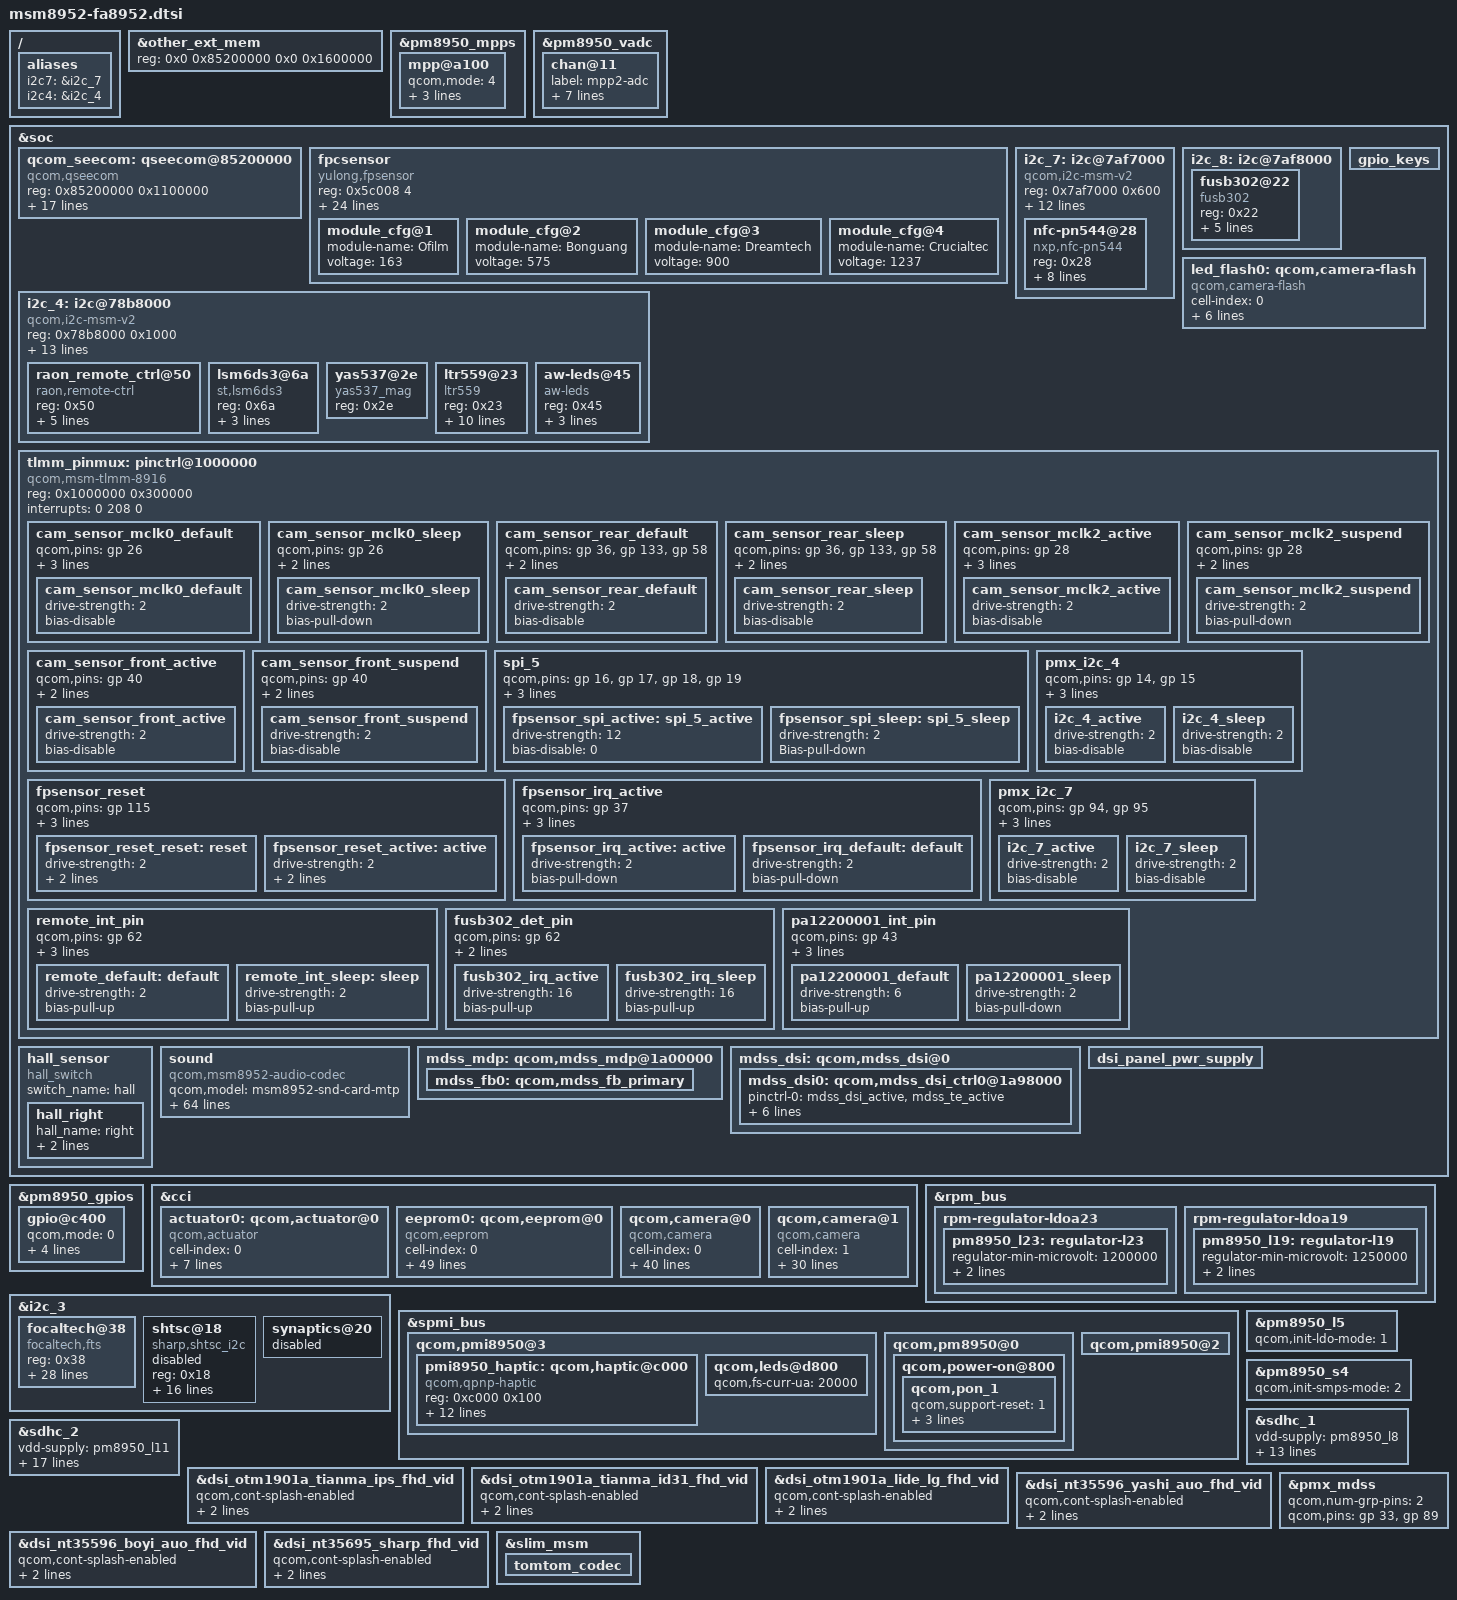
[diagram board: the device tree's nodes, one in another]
/* Copyright (c) 2014, The Linux Foundation. All rights reserved.
*
* This program is free software; you can redistribute it and/or modify
* it under the terms of the GNU General Public License version 2 and
* only version 2 as published by the Free Software Foundation.
*
* This program is distributed in the hope that it will be useful,
* but WITHOUT ANY WARRANTY; without even the implied warranty of
* MERCHANTABILITY or FITNESS FOR A PARTICULAR PURPOSE.  See the
* GNU General Public License for more details.
*/

/* project fa8952 */

/*    add by pengchaojin for NFC   */
/ {
	aliases {
		i2c7 = &i2c_7;
		i2c4 = &i2c_4;
		/delete-property/ spi0;
		/delete-property/ i2c5;
	};
	  /delete-node/ sdhc_2;
};
/*modify by huangrui*/
/*&other_ext_mem{
reg = <0x0 0x84A00000 0x0 0x1e00000>;
};*/
&other_ext_mem{
reg = <0x0 0x85200000 0x0 0x1600000>;
};

&pm8950_mpps {
         mpp@a100 {
                   status = "okay";
                   qcom,mode = <4>;
                   qcom,src-sel = <0>;
                   qcom,ain-route = <1>;
                   qcom,master-en = <1>;
         };
};

&pm8950_vadc { 
         chan@11 {
                   label ="mpp2-adc";
                   reg = <0x11>;
                   qcom,decimation = <0>;
                   qcom,pre-div-channel-scaling = <0>;
                   qcom,calibration-type = "absolute";
                   qcom,scale-function = <0>;
                   qcom,hw-settle-time = <1>;
                   qcom,fast-avg-setup = <2>;
         };
};
/* Begin add pinmux for i2c-7 */
&tlmm_pinmux {
spi_5 {
				 qcom,pins = <&gp 16>, <&gp 17>,<&gp 18>, <&gp 19>;
				 qcom,num-grp-pins = <4>;
				 qcom,pin-func = <1>;
				 label = "spi_5";
				 fpsensor_spi_active: spi_5_active {
						 drive-strength = <12>;
						 bias-disable = <0>; /* No PULL */
				 };
				 fpsensor_spi_sleep: spi_5_sleep {
						 drive-strength = <2>;
						Bias-pull-down;/*pull down*/
				 };
		};





fpsensor_reset {
			qcom,pins = <&gp 115>;
			qcom,num-grp-pins = <1>;
			qcom,pin-func = <0>;
			label = "fpsensor_reset";
			fpsensor_reset_reset: reset {
				drive-strength = <2>;
				bias-disable;
				output-low;
			};
			fpsensor_reset_active: active {
				drive-strength = <2>;
				bias-disable;
				output-high;
			};
		};

		fpsensor_irq_active {
			qcom,pins = <&gp 37>;
			qcom,num-grp-pins = <1>;
			qcom,pin-func = <0>;
			label = "fpsensor_irq_active";
			fpsensor_irq_active: active {
				drive-strength = <2>;
				bias-pull-down;
			};
			fpsensor_irq_default: default {
				drive-strength = <2>;
				bias-pull-down;
			};
		};
	
	 pmx_i2c_4 {
                 qcom,pins = <&gp 14>, <&gp 15>; /* SDA, SCL */
                 qcom,num-grp-pins = <2>;
                 qcom,pin-func = <3>;
                 label = "pmx_i2c_4";

                 i2c_4_active: i2c_4_active {
                         drive-strength = <2>;
                         bias-disable;
                    };

                  i2c_4_sleep: i2c_4_sleep {
                         drive-strength = <2>;
                         bias-disable;
                    };
          };
	pmx_i2c_7 {
		/* CLK, DATA */
		qcom,pins = <&gp 94>, <&gp 95>;
		qcom,num-grp-pins = <2>;
		qcom,pin-func = <4>;
		label = "pmx_i2c_7";
		/* active state */
		i2c_7_active: i2c_7_active{
			drive-strength = <2>; /* 2 MA */
			bias-disable; /* No PULL */
		};
		/* suspended state */
		i2c_7_sleep: i2c_7_sleep {
			drive-strength = <2>; /* 2 MA */
			bias-disable; /* No PULL */
		};
	};
	  remote_int_pin {
                qcom,pins = <&gp 62>;
                qcom,num-grp-pins = <1>;
                qcom,pin-func = <0>;
                label = "remote_wakeup_gpio";
                remote_default: default {
                        drive-strength = <2>;   /* 2 MA */
                        bias-pull-up;           /* PULL UP*/
                };
                remote_int_sleep: sleep {
                        drive-strength = <2>;   /* 2 MA */
                        bias-pull-up;           /* PULL UP */
                };
        };
        
	

	fusb302_det_pin {
		qcom,pins = <&gp 62>;
		qcom,num-grp-pins = <1>;
		label = "det-gpio";
		fusb302_irq_active: fusb302_irq_active {
			drive-strength = <16>;
			bias-pull-up;
		};
		fusb302_irq_sleep: fusb302_irq_sleep {
			drive-strength = <16>;
			bias-pull-up;
		};
	};
};
/* End add pinmux for i2c-7 */

/* Begin add i2c-7 bus */
&soc {

/*modyfy by huangrui*/
  /delete-node/ spi@78B5000;
  /delete-node/ i2c@7af5000;
    
  /delete-node/  qseecom@85e00000;
  /*qcom_seecom: qseecom@84A00000*/
   qcom_seecom: qseecom@85200000 {
		compatible = "qcom,qseecom";
		/*reg = <0x84A00000 0x1900000>;*/
		reg = <0x85200000 0x1100000>;
		reg-names = "secapp-region";
		qcom,hlos-num-ce-hw-instances = <1>;
		qcom,hlos-ce-hw-instance = <0>;
		qcom,qsee-ce-hw-instance = <0>;
		qcom,disk-encrypt-pipe-pair = <2>;
		qcom,support-fde;
		qcom,msm-bus,name = "qseecom-noc";
		qcom,msm-bus,num-cases = <4>;
		qcom,msm-bus,num-paths = <1>;
		qcom,support-bus-scaling;
		qcom,msm-bus,vectors-KBps =
			<55 512 0 0>,
			<55 512 0 0>,
			<55 512 120000 1200000>,
			<55 512 393600 3936000>;
		clocks = <&clock_gcc clk_crypto_clk_src>,
			 <&clock_gcc clk_gcc_crypto_clk>,
			 <&clock_gcc clk_gcc_crypto_ahb_clk>,
			 <&clock_gcc clk_gcc_crypto_axi_clk>;
		clock-names = "core_clk_src", "core_clk",
				"iface_clk", "bus_clk";
		qcom,ce-opp-freq = <100000000>;
	};


fpcsensor {
			status = "ok";
			compatible = "yulong,fpsensor";
			reg = <0x5c008 4>;//8939:0x5c008, 899x:0xFC4B81F0
			reg-names = "msmcpusn";
			spi-max-frequency = <10000000>;
			sensor-name = "fpc1021";//fpc1021,fpc1140,fpc1022;goodix318m,goodix518m	
			vdd_io-supply   = <&pm8950_l6>;
			//vdd_3p3-supply  = <&pm8916_l6>;
			fpsensor-vreg-name = "vdd_io";// "vdd_3p3";
			fpsensor-vreg-min-voltage = <1800000>;//3300000
			fpsensor-vreg-max-voltage = <1800000>;//3300000
			fpsensor-vreg-op-mode = <50000>;//50000
			gpio_rst    = <&msm_gpio 115 0>;
			gpio_irq    = <&msm_gpio 37 0>;
			clock-names = "iface_clk", "core_clk";
			clocks = <&clock_gcc clk_gcc_blsp2_ahb_clk>,
					 <&clock_gcc clk_gcc_blsp2_qup1_spi_apps_clk>;
			master-id = <84>;
			qcom,use-pinctrl;
			pinctrl-names = "fpsensor_reset_reset",
					"fpsensor_reset_active",
					"fpsensor_irq_active",
					"fpsensor_irq_default",
					"fpsensor_spi_active",
					"fpsensor_spi_sleep";
			pinctrl-0 = <&fpsensor_reset_reset>;
			pinctrl-1 = <&fpsensor_reset_active>;
			pinctrl-2 = <&fpsensor_irq_active>;
			pinctrl-3 = <&fpsensor_irq_default>;
			pinctrl-4 = <&fpsensor_spi_active>;
			pinctrl-5 = <&fpsensor_spi_sleep>;
			linux,code = <102 114 116 139 231 272>;//home volumedown power mouse 
			qcom,fpsensor-vadc = <&pm8950_vadc>;
			id-vadc-channel = <17>;	//p_mux2_1_1	
			interrupt-parent = <&msm_gpio>;
			interrupts = <37 0x0>;
			module_cfg@1{
				module-name = "Ofilm";
				voltage = <163>;
			};
			module_cfg@2{
				module-name = "Bonguang";
				voltage = <575>;
			};
			module_cfg@3{
				module-name = "Dreamtech";
				voltage = <900>;
			};			
			module_cfg@4{
				module-name = "Crucialtec";
				voltage = <1237>;
			};
	};
	
	i2c_4: i2c@78b8000 { /* BLSP1 QUP4 */
                compatible = "qcom,i2c-msm-v2";
                #address-cells = <1>;
                #size-cells = <0>;
                reg-names = "qup_phys_addr";
                reg = <0x78b8000 0x1000>;
                interrupt-names = "qup_irq";
                interrupts = <0 98 0>;
                qcom,clk-freq-out = <400000>;
                qcom,clk-freq-in  = <19200000>;
                clock-names = "iface_clk", "core_clk";
                clocks = <&clock_gcc clk_gcc_blsp1_ahb_clk>,
                <&clock_gcc clk_gcc_blsp1_qup4_i2c_apps_clk>;
                qcom,use-pinctrl;
                pinctrl-names = "i2c_active", "i2c_sleep";
                pinctrl-0 = <&i2c_4_active>;
                pinctrl-1 = <&i2c_4_sleep>;
                qcom,noise-rjct-scl = <0>;
                qcom,noise-rjct-sda = <0>;
                dmas = <&dma_blsp1 10 64 0x20000020 0x20>,
                <&dma_blsp1 11 32 0x20000020 0x20>;
                dma-names = "tx", "rx";
                qcom,master-id = <86>;
                };
	i2c_7: i2c@7af7000 { /* BLSP2 QUP3 */
		compatible = "qcom,i2c-msm-v2";
		#address-cells = <1>;
		#size-cells = <0>;
		reg-names = "qup_phys_addr";
		reg = <0x7af7000 0x600>;
		interrupt-names = "qup_irq";
		interrupts = <0 301 0>;
		qcom,clk-freq-out = <400000>;
		qcom,clk-freq-in  = <19200000>;
		clock-names = "iface_clk", "core_clk";
		clocks = <&clock_gcc clk_gcc_blsp2_ahb_clk>,
			 <&clock_gcc clk_gcc_blsp2_qup3_i2c_apps_clk>;

		pinctrl-names = "i2c_active", "i2c_sleep";
		pinctrl-0 = <&i2c_7_active>;
		pinctrl-1 = <&i2c_7_sleep>;
		qcom,noise-rjct-scl = <0>;
		qcom,noise-rjct-sda = <0>;
		qcom,master-id = <84>;
		dmas = <&dma_blsp2 8 64 0x20000020 0x20>,
			<&dma_blsp2 9 32 0x20000020 0x20>;
		dma-names = "tx", "rx";
	};
	
	
	
		i2c_8: i2c@7af8000 { /* BLSP2 QUP4 */
		/* add usb type c for fusb302 */
		fusb302@22 {
			compatible = "fusb302";
			reg = <0x22>;
			usb_det = <&msm_gpio 62 0x1>;
			interrupt-parent = <&msm_gpio>;
			interrupts = <62 0>;
			interrupt-names = "usb_det_int";
			pinctrl-names = "default", "sleep";
			pinctrl-0 = <&fusb302_irq_active>;
			pinctrl-1 = <&fusb302_irq_sleep>;
		};
	};
};
/* End add i2c-7 bus */

	

/* Begin add NFC clkreq configuration */
&pm8950_gpios {
	gpio@c400 { /* GPIO 5 */
		/delete-property/ status;
		/* NFC_CLK_REQ */
                qcom,mode = <0>; /* QPNP_PIN_MODE_DIG_IN */
                qcom,pull = <5>; /* QPNP_PIN_PULL_NO */
                qcom,vin-sel = <2>; /* QPNP_PIN_VIN2 */
                qcom,src-sel = <2>; /* QPNP_PIN_SEL_FUNC_1 */
                qcom,master-en = <1>;
	};
};
/* End add NFC clkreq configuration */

/*begain YL add for sensor*/
&i2c_4{/* BLSP4*/
                /*fengdongjie add for remote control*/
        raon_remote_ctrl@50 {
                compatible = "raon,remote-ctrl";
                reg = <0x50>;
                pinctrl-names = "default","sleep";
                pinctrl-0 = <&remote_default>;
                pinctrl-1 = <&remote_int_sleep>;
                vdd_ana-supply = <&pm8950_l6>;
                raon,init-gpio = <&msm_gpio 62 0x00>; //wake up pin
                raon,reset-gpio = <&msm_gpio 88 0x00>; // reset pin
        };
};
/*end for YL add for sensor*/

/* Begin add PN547 */
&i2c_7 { /* BLSP7*/ 
	nfc-pn544@28 {
		compatible = "nxp,nfc-pn544";
		reg = <0x28>;
		nxp,irq-gpio = <&msm_gpio 42 0x00>;
		nxp,ven-gpio = <&msm_gpio 129 0x00>;
		nxp,clk-src = "BBCLK2";
		interrupt-parent = <&msm_gpio>;
		interrupts = <42 0>;
		interrupt-names = "nfc_irq";
		nxp,clkreq-gpio = <&pm8950_gpios 5 0>;
		clocks = <&clock_gcc clk_bb_clk2_pin>;
		clock-names = "ref_clk";
		nxp,firm-gpio = <&msm_gpio 131 0x00>;		
	};
};
/* End add PN547 */

/* Begin add camera dts file for 8952 platform */

&cci {

	/delete-node/ qcom,actuator@0;
	/delete-node/ qcom,actuator@1;
	/delete-node/ qcom,camera@0;
	/delete-node/ qcom,camera@1;
	/delete-node/ qcom,camera@2;
	/delete-node/ qcom,camera@78;
	/delete-node/ qcom,eeprom@0;
	/delete-node/ qcom,eeprom@1;
	/delete-node/ qcom,eeprom@2;


	actuator0: qcom,actuator@0 {
		cell-index = <0>;
		reg = <0x0>;
		compatible = "qcom,actuator";
		qcom,cci-master = <0>;
		cam_vaf-supply = <&pm8950_l17>; //cn:
		qcom,cam-vreg-name = "cam_vaf";
		qcom,cam-vreg-min-voltage = <2850000>;
		qcom,cam-vreg-max-voltage = <2850000>;
		qcom,cam-vreg-op-mode = <100000>;
	};
/*
	actuator1: qcom,actuator@1 {
		cell-index = <1>;
		reg = <0x1>;
		compatible = "qcom,actuator";
		qcom,cci-master = <1>;
		cam_vaf-supply = <&pm8950_l17>;
		qcom,cam-vreg-name = "cam_vaf";
		qcom,cam-vreg-min-voltage = <2800000>;
		qcom,cam-vreg-max-voltage = <2800000>;
		qcom,cam-vreg-op-mode = <100000>;
	};	
*/	
	
	eeprom0: qcom,eeprom@0 {
		cell-index = <0>;
		reg = <0x0>;
		qcom,eeprom-name = "samsung_s5k3m2";
		compatible = "qcom,eeprom";
		qcom,slave-addr = <0xa0>;
		qcom,i2c-freq-mode = <1>;
		qcom,cci-master = <0>;
		qcom,num-blocks = <1>;

		qcom,page0 = <0 0 0 0 0 0>;
		qcom,poll0 = <0 0 0 0 0 0>;
		qcom,saddr0 = <0xa0>;
		qcom,mem0 = <0x17F6 0x0000 2 0 1 0>;
		
		cam_vdig-supply = <&pm8950_l23>;	//for place ,actually use GPIO
		cam_vio-supply = <&pm8950_l6>;		//DOVDD	1.8
		cam_vana-supply = <&pm8950_l6>;		//for place ,actually use GPIO
		cam_vaf-supply = <&pm8950_l17>;		//VAAM	2.85
		qcom,cam-vreg-name = "cam_vdig", "cam_vio", "cam_vana", "cam_vaf";
		qcom,cam-vreg-min-voltage = <1200000 1800000 1800000 2850000>;
		qcom,cam-vreg-max-voltage = <1200000 1800000 1800000 2850000>;
		qcom,cam-vreg-op-mode = <200000 100000 100000 100000>;
		pinctrl-names = "cam_default", "cam_suspend";
		pinctrl-0 = <&cam_sensor_mclk0_default
				&cam_sensor_rear_default>;
		pinctrl-1 = <&cam_sensor_mclk0_sleep &cam_sensor_rear_sleep>;
		qcom,gpio-no-mux = <0>;
		gpios = <&msm_gpio 26 0>,	//CAM_MCLK0
			<&msm_gpio 36 0>,		//CAM0_RST
			<&msm_gpio 133 0>,		//MCAM_DVDD_EN
			<&msm_gpio 68 0>;		//MCAM_AVDD_EN

		qcom,gpio-reset = <1>;
		qcom,gpio-vdig = <2>;
		qcom,gpio-vana = <3>;
		qcom,gpio-req-tbl-num = <0 1 2 3>;
		qcom,gpio-req-tbl-flags = <1 0 0 0>;
		
		qcom,gpio-req-tbl-label = "CAMIF_MCLK0",
			"CAM_RESET0",
			"CAM_VDIG0",
			"CAM_VANA0";

                qcom,cam-power-seq-type = "sensor_gpio",
                    "sensor_vreg",
                    "sensor_gpio",
                    "sensor_gpio",
                    "sensor_vreg",
                    "sensor_clk",
                    "sensor_gpio",
                    "sensor_i2c_mux";
                qcom,cam-power-seq-val = "sensor_gpio_reset",
                    "cam_vio",
                    "sensor_gpio_vdig",
                    "sensor_gpio_vana",
                    "cam_vaf",
                    "sensor_cam_mclk",
                    "sensor_gpio_reset", 
                    "none";
                qcom,cam-power-seq-cfg-val = <0 1 1 1 1 24000000 1 0>;
                qcom,cam-power-seq-delay = <5 5 5 5 5 5 5 5>;
			
		clocks = <&clock_gcc clk_mclk0_clk_src>,
			     <&clock_gcc clk_gcc_camss_mclk0_clk>;
		clock-names = "cam_src_clk", "cam_clk";
	};
	
	qcom,camera@0 {
		cell-index = <0>;
		compatible = "qcom,camera";
		reg = <0x0>;
		qcom,csiphy-sd-index = <0>;
		qcom,csid-sd-index = <0>;
		qcom,mount-angle = <90>;
		qcom,eeprom-src = <&eeprom0>;
		qcom,actuator-src = <&actuator0>;
		qcom,led-flash-src = <&led_flash0>;
		cam_vdig-supply = <&pm8950_l23>;	//for place ,actually use GPIO 1.05V
		cam_vio-supply = <&pm8950_l6>;		//DOVDD	1.8
		cam_vana-supply = <&pm8950_l6>;		//for place ,actually use GPIO
		cam_vaf-supply = <&pm8950_l17>;		//VAAM	2.85
		qcom,cam-vreg-name = "cam_vdig", "cam_vio", "cam_vana", "cam_vaf";
		qcom,cam-vreg-min-voltage = <1200000 1800000 1800000 2850000>;
		qcom,cam-vreg-max-voltage = <1200000 1800000 1800000 2850000>;
		qcom,cam-vreg-op-mode = <200000 100000 100000 100000>;
		pinctrl-names = "cam_default", "cam_suspend";
		pinctrl-0 = <&cam_sensor_mclk0_default
				&cam_sensor_rear_default>;
		pinctrl-1 = <&cam_sensor_mclk0_sleep &cam_sensor_rear_sleep>;
		qcom,gpio-no-mux = <0>;
		gpios = <&msm_gpio 26 0>,	//CAM_MCLK0
			<&msm_gpio 36 0>,		//CAM0_RST
			<&msm_gpio 133 0>,		//MCAM_DVDD_EN
			<&msm_gpio 68 0>;		//MCAM_AVDD_EN

		qcom,gpio-reset = <1>;
		qcom,gpio-vdig = <2>;
		qcom,gpio-vana = <3>;
		qcom,gpio-req-tbl-num = <0 1 2 3>;
		qcom,gpio-req-tbl-flags = <1 0 0 0>;

		qcom,gpio-req-tbl-label = "CAMIF_MCLK0",
			"CAM_RESET0",
			"CAM_VDIG0",
			"CAM_VANA0";

		qcom,csi-lane-assign = <0x4320>;
		qcom,csi-lane-mask = <0x1f>;
		qcom,sensor-position = <0>;
		qcom,sensor-mode = <0>;
		qcom,cci-master = <0>;
		status = "ok";
		clocks = <&clock_gcc clk_mclk0_clk_src>,
			     <&clock_gcc clk_gcc_camss_mclk0_clk>;
		clock-names = "cam_src_clk", "cam_clk";
	};
	
	//OV8865
	qcom,camera@1 {
		cell-index = <1>;
		compatible = "qcom,camera";
		reg = <0x1>;
		qcom,csiphy-sd-index = <1>;
		qcom,csid-sd-index = <1>;
		qcom,mount-angle = <270>;
				
		cam_vdig-supply = <&pm8950_l23>;	//DVDD	1.2
		cam_vio-supply = <&pm8950_l6>;		//DOVDD	1.8
		cam_vana-supply = <&pm8950_l22>;	//AVDD 2.85

		qcom,cam-vreg-name = "cam_vdig", "cam_vio", "cam_vana";
		qcom,cam-vreg-min-voltage = <1200000 1800000 2800000>;
		qcom,cam-vreg-max-voltage = <1200000 1800000 2800000>;
		qcom,cam-vreg-op-mode = <105000 105000 80000>;
		qcom,gpio-no-mux = <0>;
		pinctrl-names = "cam_default", "cam_suspend";
		pinctrl-0 = <&cam_sensor_mclk2_active &cam_sensor_front_active>;
		pinctrl-1 = <&cam_sensor_mclk2_suspend &cam_sensor_front_suspend>;
		gpios = <&msm_gpio 28 0>,
			<&msm_gpio 40 0>; //RESET

		qcom,gpio-reset = <1>;
		qcom,gpio-req-tbl-num = <0 1>;
		qcom,gpio-req-tbl-flags = <1 0>;
		qcom,gpio-req-tbl-label = "CAMIF_MCLK2",
					  "CAM_RESET2";
		qcom,sensor-position = <1>;
		qcom,sensor-mode = <0>;
		qcom,cci-master = <1>;
		status = "ok";
		clocks = <&clock_gcc clk_mclk2_clk_src>,
			<&clock_gcc clk_gcc_camss_mclk2_clk>;
		clock-names = "cam_src_clk", "cam_clk";
	};	
};

&rpm_bus {
	rpm-regulator-ldoa23 {
		status = "okay";
		pm8950_l23: regulator-l23 {
			regulator-min-microvolt = <1200000>;
			regulator-max-microvolt = <1200000>;
			qcom,init-voltage = <1200000>;
			status = "okay";
		};
	};
};

&soc {
	/delete-node/ qcom,camera-flash;
	
	gpio_keys {
		/delete-node/ cam_snapshot;
		/delete-node/ cam_focus;
	};
	
	led_flash0: qcom,camera-flash {
		cell-index = <0>;
		compatible = "qcom,camera-flash";
		qcom,flash-type = <1>;
		qcom,flash-source = <&pmi8950_flash0 &pmi8950_flash1>;
		qcom,torch-source = <&pmi8950_torch0 &pmi8950_torch1>;
		qcom,switch-source = <&pmi8950_switch>;
	};	
		
	tlmm_pinmux: pinctrl@1000000 {
		compatible = "qcom,msm-tlmm-8916";
		reg = <0x1000000 0x300000>;
		interrupts = <0 208 0>;
		
          /* finger */
           /delete-node/ spi0_active;
           /delete-node/ spi0_suspend;
           /delete-node/ spi0_cs0_active;
           /delete-node/ spi0_cs0_suspend;
           
		/*sensors */
		cam_sensor_mclk0_default {
			/* MCLK0 */
			qcom,pins = <&gp 26>;
			qcom,num-grp-pins = <1>;
			qcom,pin-func = <1>;
			label = "cam_sensor_mclk0_default";
			/* active state */
			cam_sensor_mclk0_default: cam_sensor_mclk0_default {
				drive-strength = <2>; /* 2 MA */
				bias-disable; /* No PULL */
			};
		};

		cam_sensor_mclk0_sleep {
			/* MCLK0 */
			qcom,pins = <&gp 26>;
			qcom,num-grp-pins = <1>;
			label = "cam_sensor_mclk0_sleep";
			/*suspended state */
			cam_sensor_mclk0_sleep: cam_sensor_mclk0_sleep {
				drive-strength = <2>; /* 2 MA */
				bias-pull-down; /* PULL DOWN */
			};
		};

		cam_sensor_rear_default {
			/* RESET, MCAM_DVDD_EN, MCAM_AVDD_EN */
			qcom,pins = <&gp 36>,  <&gp 133>, <&gp 58>;
			qcom,num-grp-pins = <3>;
			label = "cam_sensor_rear_default";
			/* active state */
			cam_sensor_rear_default: cam_sensor_rear_default {
				drive-strength = <2>; /* 2 MA */
				bias-disable; /* No PULL */
			};
		};

		cam_sensor_rear_sleep {
			/* RESET, MCAM_DVDD_EN ,MCAM_AVDD_EN */
			qcom,pins = <&gp 36>, <&gp 133>, <&gp 58>;
			qcom,num-grp-pins = <3>;
			label = "cam_sensor_rear_sleep";
			/*suspended state */
			cam_sensor_rear_sleep: cam_sensor_rear_sleep {
				drive-strength = <2>; /* 2 MA */
				bias-disable; /* No PULL */
			};
		};
		
		cam_sensor_mclk2_active {
			/* mclk2 */
			qcom,pins = <&gp 28>;
			qcom,num-grp-pins = <1>;
			qcom,pin-func = <1>;
			label = "cam_sensor_mclk2_active";
			/* active state */
			cam_sensor_mclk2_active: cam_sensor_mclk2_active {
				drive-strength = <2>; /* 2 MA */
				bias-disable; /* No PULL */
			};
		};

		cam_sensor_mclk2_suspend {
			/* mclk2 */
			qcom,pins = <&gp 28>;
			qcom,num-grp-pins = <1>;
			label = "cam_sensor_mclk2_suspend";
			/* suspend state */
			cam_sensor_mclk2_suspend: cam_sensor_mclk2_suspend {
				drive-strength = <2>; /* 2 MA */
				bias-pull-down; /* PULL DOWN */
			};
		};
		
		cam_sensor_front_active {
			/* RESET */
			qcom,pins = <&gp 40>;
			qcom,num-grp-pins = <1>;
			label = "cam_sensor_front_active";
			/* active state */
			cam_sensor_front_active: cam_sensor_front_active {
				drive-strength = <2>; /* 2 MA */
				bias-disable; /* No PULL */
			};
		};

		cam_sensor_front_suspend {
			/* RESET */
			qcom,pins = <&gp 40>;
			qcom,num-grp-pins = <1>;
			label = "cam_sensor_front_suspend";
			/*suspended state */
			cam_sensor_front_suspend: cam_sensor_front_suspend {
				drive-strength = <2>; /* 2 MA */
				bias-disable; /* No PULL */
			};
		};
		
	};
};	

/* End add camera dts file for 8952 platform */

/* beg yinchao add dts */
&soc {
    hall_sensor {
        compatible = "hall_switch";
        switch_name = "hall";
        hall_right {
            hall_name = "right";
            gpios = <&msm_gpio 63 0x1>;
            wakeup = <1>;
        };
    };
};

&i2c_3 { /* BLSP1 QUP3 */
	focaltech@38 {
			compatible = "focaltech,fts";
			reg = <0x38>;
			interrupt-parent = <&msm_gpio>;
			interrupts = <65 0x2008>;
			vdd-supply = <&pm8950_l17>;
			vcc_i2c-supply = <&pm8950_l6>;
			/* pins used by touchscreen */
			pinctrl-names = "pmx_ts_active","pmx_ts_suspend","pmx_ts_release";
			pinctrl-0 = <&ts_int_active &ts_reset_active>;
			pinctrl-1 = <&ts_int_suspend &ts_reset_suspend>;
			pinctrl-2 = <&ts_release>;
			focaltech,name = "ft5446";
			focaltech,family-id = <0x14>;
			focaltech,reset-gpio = <&msm_gpio 64 0x0>;
			focaltech,irq-gpio = <&msm_gpio 65 0x2008>;
			focaltech,display-coords = <0 0 1080 1920>;
			focaltech,panel-coords = <0 0 1080 2098>;
			focaltech,button-map= <270 540 810>;
			focaltech,no-force-update;
			focaltech,i2c-pull-up;
			focaltech,group-id = <1>;
			focaltech,hard-reset-delay-ms = <20>;
			focaltech,soft-reset-delay-ms = <200>;
			focaltech,num-max-touches = <5>;
			focaltech,fw-delay-aa-ms = <30>;
			focaltech,fw-delay-55-ms = <30>;
			focaltech,fw-upgrade-id1 = <0x11>;
			focaltech,fw-upgrade-id2 = <0x11>;
			focaltech,fw-delay-readid-ms = <10>;
			focaltech,fw-delay-era-flsh-ms = <2000>;
			focaltech,fw-auto-cal;
			focaltech,ignore-id-check;
		};
	      shtsc@18 {
                        compatible = "sharp,shtsc_i2c";
			status = "disabled";
                        reg = <0x18>;
                        interrupt-parent = <&msm_gpio>;
                        interrupts = <65 0x2008>;// high-level trigger. but hard coded in the source.
                        vdd-supply = <&pm8950_l17>;
                        vcc_i2c-supply = <&pm8950_l6>;
                        sharp,reset-gpio = <&msm_gpio 64 0x00>;
                        sharp,irq-gpio = <&msm_gpio 65 0x2008>;
                        pinctrl-names = "pmx_ts_active","pmx_ts_suspend";
                        pinctrl-0 = <&ts_int_active &ts_reset_active>;
                        pinctrl-1 = <&ts_int_suspend &ts_reset_suspend>;
                        sharp,panel-coords = <0 0 1079 1919>; // depends on an LCD resolution (0 0 Xmax-1 Ymax-1)
                        sharp,display-coords = <0 0 1079 1919>; // depends on an LCD resolution (0 0 Xmax-1 Ymax-1)
                        sharp,i2c-pull-up;
                        ts_touch_num_max = <10>;
                        ts_pressure_max = <65535>;
                        ts_flip_x = <0>;
                        ts_flip_y = <0>;
                        ts_swap_xy = <0>;

                };
};

&i2c_4 {
    /* accel & gyro */
    lsm6ds3@6a {
        compatible = "st,lsm6ds3";
        reg = <0x6a>;
        interrupt-parents = <&msm_gpio>;
        interrupts = <45 0x2>;
        st,drdy-int-pin = <&msm_gpio 45 0x00>;
    };

    /* mag */
    yas537@2e {
        compatible = "yas537_mag";
        reg = <0x2e>;
    };

    /*Proximity & Light*/
                 ltr559@23 {
                         compatible = "ltr559";
                         reg = <0x23>;
                         pinctrl-names = "default","sleep";
                         pinctrl-0 = <&ltr559_default>;
                         pinctrl-1 = <&ltr559_sleep>;
                         vdd_ana-supply = <&pm8916_l17>;
                         vcc_i2c-supply = <&pm8916_l6>;
                         interrupt-parent = <&msm_gpio>;
                         interrupts = <43 0x2>;
                         ltr559,gpio_int = <&msm_gpio 43 0x00>;
                         ltr559,irq_flags = <0x2>;
                         ltr559,cfgs = <
                                 130        /*prox_threshold_hi = 130*/
                                 110        /*prox_threshold_lo = 110*/
                                 0            /*prox_factory_threshold_hi = 0*/
                                 0            /*prox_factory_threshold_lo = 0*/
                                 0x20       /*interrupt_persist = 0x20*/
                                 0x7F       /*ps_led = 0x7F*/
                                 0x0A       /*ps_n_pulses = 0x0F*/
                                 0x00       /*ps_meas_rate = 0x00*/
                                 0x02       /*als_meas_rate = 0x02*/
                                 30          /*ltr559_proximity_low_offset0 = 30*/
                                 50        /*ltr559_proximity_high_offset0 = 100*/
                                 130        /*ltr559_proximity_low_offset1 = 130*/
                                 150        /*ltr559_proximity_high_offset1 = 150*/
                                 45          /*ltr559_proximity_low_offset2 =45*/
                                 55          /*ltr559_proximity_high_offset2 =55*/
                                 800        /*ltr559_struct_noise_threshold = 800/1200*/
                                 >;
                 };	
   /*aw3013 rgb light*/
 aw-leds@45 {
		compatible =   "aw-leds";
		reg = <0x45>;
		vdd_ana-supply = <&pm8950_l10>;
		aw_leds,cfgs = <
				/*1018led_red_sw ,set red sw GPIO*/
				0x04/*aw_blue_on */
				0x03/*aw_blue_off */
				0x33 /*AW_BLUE_CTRL,AW_LED2_CTRL=0x33 */
				0x36/*AW_BLUE_PWM,AW_PWM2=0x36 */
				0x3D /*AW_BLUE_T0 ,AW_LED2_T0=0x3D*/
				0x3E /*AW_BLUE_T1 ,AW_LED2_T1=0x3E*/
				0x3F /*AW_BLUE_T2 ,AW_LED2_T2=0x3F*/
				0x02/*aw_green_on */
				0x05/*aw_green_off */
				0x32 /*AW_GREEN_CTRL,AW_LED1_CTRL =0x32 */
				0x35/*AW_GREEN_PWM ,AW_PWM1=0x35*/
				0x3A /*AW_GREEN_T0 ,AW_LED1_T0=0x3A*/
				0x3B /*AW_GREEN_T1 ,AW_LED1_T1=0x3B*/
				0x3C /*AW_GREEN_T2 ,AW_LED1_T2=0x3C*/
			    	0x01/*aw_red_on */
			    	0x06/*aw_red_off ,0x02*/
				0x31 /*AW_RED_CTRL,AW_LED0_CTRL=0x31 */
				0x34/*AW_RED_PWM ,AW_PWM0=0x34*/
				0x37 /*AW_RED_T0 ,AW_LED0_T0=0x37*/
				0x38 /*AW_RED_T1 ,AW_LED0_T0=0x38*/
				0x39 /*AW_RED_T2 ,AW_LED0_T0=0x39*/
			>;
		};
};

&i2c_3 {
synaptics@20 {
        status = "disabled";
};
};

&tlmm_pinmux {
    pa12200001_int_pin {
        /* Ambient light and proximity sensor pa12200001 */
        qcom,pins = <&gp 43>;
        qcom,pin-func = <0>;
        qcom,num-grp-pins = <1>;
        label = "pa12200001-irq";

        pa12200001_default: pa12200001_default {
            drive-strength = <6>;
            bias-pull-up;
        };

        pa12200001_sleep: pa12200001_sleep {
            drive-strength = <2>;
            bias-pull-down;
        };
    };
};
/* end yinchao add dts */

/* anxinlong add dts for vibrator start*/
&spmi_bus {
qcom,pmi8950@3 {
      pmi8950_haptic: qcom,haptic@c000 {
			compatible = "qcom,qpnp-haptic";
			reg = <0xc000 0x100>;
			interrupts = <0x3 0xc0 0x0>,
					<0x3 0xc0 0x1>;
			interrupt-names = "sc-irq", "play-irq";
			qcom,play-mode = "direct";
			qcom,wave-play-rate-us = <4255>;
			qcom,actuator-type = "erm";
			qcom,wave-shape = "square";
			qcom,vmax-mv = <2784>;
			qcom,ilim-ma = <100>;
			qcom,sc-deb-cycles = <8>;
			//qcom,int-pwm-freq-khz = <505>;
			//qcom,en-brake;
			qcom,brake-pattern = [03 03 00 00];
			//qcom,use-play-irq;
			//qcom,use-sc-irq;
			qcom,wave-samples = [3e 3e 3e 3e 3e 3e 3e 3e];
			qcom,wave-rep-cnt = <1>;
			qcom,wave-samp-rep-cnt = <1>;
		};
            };
    };

/* anxinlong add dts for vibrator end*/
/* anxinlong@yulong.com add dts for audio 20150709 start */
&soc {

     sound {
		compatible = "qcom,msm8952-audio-codec";
		qcom,model = "msm8952-snd-card-mtp";
		reg = <0xc051000 0x4>,
		      <0xc051004 0x4>,
		      <0xc055000 0x4>,
		      <0xc052000 0x4>;
		reg-names = "csr_gp_io_mux_mic_ctl",
			    "csr_gp_io_mux_spkr_ctl",
			    "csr_gp_io_lpaif_pri_pcm_pri_mode_muxsel",
			    "csr_gp_io_mux_quin_ctl";

		qcom,msm-ext-pa = "primary";
		qcom,msm-mclk-freq = <9600000>;
		qcom,msm-mbhc-hphl-swh = <1>;
		qcom,msm-mbhc-gnd-swh = <1>;
		qcom,msm-hs-micbias-type = "external";
		qcom,msm-micbias1-ext-cap;
        qcom,msm-spk-boost-ctl = <&msm_gpio 132 0>;
		qcom,audio-routing =
			"RX_BIAS", "MCLK",
			"SPK_RX_BIAS", "MCLK",
			"INT_LDO_H", "MCLK",
			"MIC BIAS External", "Handset Mic",
			"MIC BIAS External2", "Headset Mic",
			"MIC BIAS External", "Secondary Mic",
			"AMIC1", "MIC BIAS External",
			"AMIC2", "MIC BIAS External2",
			"AMIC3", "MIC BIAS External";
		qcom,msm-gpios =
			"pri_i2s",
			"us_eu_gpio";
		qcom,pinctrl-names =
			"all_off",
			"pri_i2s_act",
			"us_eu_gpio_act",
			"pri_i2s_us_eu_gpio_act";
		pinctrl-names =
			"all_off",
			"pri_i2s_act",
			"us_eu_gpio_act",
			"pri_i2s_us_eu_gpio_act";
		pinctrl-0 = <&cdc_pdm_lines_sus &cdc_pdm_lines_2_sus &cross_conn_det_sus>;
		pinctrl-1 = <&cdc_pdm_lines_act &cdc_pdm_lines_2_act &cross_conn_det_sus>;
		pinctrl-2 = <&cdc_pdm_lines_sus &cdc_pdm_lines_2_sus &cross_conn_det_act>;
		pinctrl-3 = <&cdc_pdm_lines_act &cdc_pdm_lines_2_act &cross_conn_det_act>;
		qcom,cdc-us-euro-gpios = <&msm_gpio 63 0>;
		asoc-platform = <&pcm0>, <&pcm1>, <&pcm2>, <&voip>, <&voice>,
				<&loopback>, <&compress>, <&hostless>,
				<&afe>, <&lsm>, <&routing>, <&lpa>,
				<&voice_svc>;
		asoc-platform-names = "msm-pcm-dsp.0", "msm-pcm-dsp.1", "msm-pcm-dsp.2",
				"msm-voip-dsp", "msm-pcm-voice", "msm-pcm-loopback",
				"msm-compress-dsp", "msm-pcm-hostless", "msm-pcm-afe",
				"msm-lsm-client", "msm-pcm-routing", "msm-pcm-lpa",
				"msm-voice-svc";
		asoc-cpu = <&dai_pri_auxpcm>, <&dai_hdmi>,
				<&dai_mi2s0>, <&dai_mi2s1>, <&dai_mi2s2>, <&dai_mi2s3>,
				<&dai_mi2s5>,<&dai_mi2s6>,
				<&sb_0_rx>, <&sb_0_tx>, <&sb_1_rx>, <&sb_1_tx>,
				<&sb_3_rx>, <&sb_3_tx>, <&sb_4_rx>, <&sb_4_tx>,
				<&bt_sco_rx>, <&bt_sco_tx>, <&int_fm_rx>, <&int_fm_tx>,
				<&afe_pcm_rx>, <&afe_pcm_tx>, <&afe_proxy_rx>, <&afe_proxy_tx>,
				<&incall_record_rx>, <&incall_record_tx>, <&incall_music_rx>,
				<&incall_music_2_rx>;
		asoc-cpu-names = "msm-dai-q6-auxpcm.1", "msm-dai-q6-hdmi.8",
				"msm-dai-q6-mi2s.0", "msm-dai-q6-mi2s.1",
				"msm-dai-q6-mi2s.2", "msm-dai-q6-mi2s.3",
				"msm-dai-q6-mi2s.5","msm-dai-q6-mi2s.6",
				"msm-dai-q6-dev.16384", "msm-dai-q6-dev.16385",
				"msm-dai-q6-dev.16386", "msm-dai-q6-dev.16387",
				"msm-dai-q6-dev.16390", "msm-dai-q6-dev.16391",
				"msm-dai-q6-dev.16392", "msm-dai-q6-dev.16393",
				"msm-dai-q6-dev.12288", "msm-dai-q6-dev.12289",
				"msm-dai-q6-dev.12292", "msm-dai-q6-dev.12293",
				"msm-dai-q6-dev.224", "msm-dai-q6-dev.225",
				"msm-dai-q6-dev.241", "msm-dai-q6-dev.240",
				"msm-dai-q6-dev.32771", "msm-dai-q6-dev.32772",
				"msm-dai-q6-dev.32773", "msm-dai-q6-dev.32770";
		asoc-codec = <&stub_codec>, <&pm8950_cajon_dig>;
		asoc-codec-names = "msm-stub-codec.1", "cajon_codec";
        /delete-property/ asoc-wsa-codec-names;
        /delete-property/ asoc-wsa-codec-prefixes;
        /delete-property/ msm-vdd-wsa-switch-supply;
        /delete-property/ qcom,msm-vdd-wsa-switch-voltage;
        /delete-property/ qcom,msm-vdd-wsa-switch-current;
	};
	
	 i2c@7af8000 {
                /delete-node/ wsa881x-i2c-codec@e;
                /delete-node/ wsa881x-i2c-codec@44;
                /delete-node/ wsa881x-i2c-codec@f;
                /delete-node/ wsa881x-i2c-codec@45;
               };
};
/* anxinlong@yulong.com add dts for audio 20150709 end */

/* wangyadong add dts for ldo19 begin */
&rpm_bus {
	rpm-regulator-ldoa19 {
		status = "okay";
		pm8950_l19: regulator-l19 {
			regulator-min-microvolt = <1250000>;
			regulator-max-microvolt = <1350000>;
			qcom,init-voltage = <1350000>;
			status = "okay";
		};
	};

};
/* wangyadong add dts for ldo19 end */
/* wangyadong add dts for ldo5 & S4 begin */
&pm8950_l5 {
        qcom,init-ldo-mode = <1>; /* NPM MODE */
};

&pm8950_s4{
        qcom,init-smps-mode = <2>;/* PWM MODE */
};
/* wangyadong add dts for ldo19 end */

/* wangyadong add dts for mmc0 & mmc1 begin */
&sdhc_1 {
	vdd-supply = <&pm8950_l8>;
        qcom,vdd-always-on;
	qcom,vdd-voltage-level = <2900000 2900000>;
	qcom,vdd-current-level = <200 570000>;

	vdd-io-supply = <&pm8950_l5>;
	qcom,vdd-io-always-on;
	qcom,vdd-io-lpm-sup;
	qcom,vdd-io-voltage-level = <1800000 1800000>;
	qcom,vdd-io-current-level = <200 325000>;

	pinctrl-names = "active", "sleep";
	pinctrl-0 = <&sdc1_clk_on &sdc1_cmd_on &sdc1_data_on &sdc1_rclk_on>;
	pinctrl-1 = <&sdc1_clk_off &sdc1_cmd_off &sdc1_data_off &sdc1_rclk_off>;

	qcom,nonremovable;

	status = "ok";
};

&sdhc_2 {
	vdd-supply = <&pm8950_l11>;
	qcom,vdd-voltage-level = <2950000 2950000>;
	qcom,vdd-current-level = <15000 400000>;

	vdd-io-supply = <&pm8950_l12>;
	qcom,vdd-io-voltage-level = <1800000 2950000>;
	qcom,vdd-io-current-level = <200 22000>;

	pinctrl-names = "active", "sleep";
	pinctrl-0 = <&sdc2_clk_on &sdc2_cmd_on &sdc2_data_on &sdc2_cd_on>;
	pinctrl-1 = <&sdc2_clk_off &sdc2_cmd_off &sdc2_data_off &sdc2_cd_off>;

	#address-cells = <0>;
	interrupt-parent = <&sdhc_2>;
	interrupts = <0 1 2>;
	#interrupt-cells = <1>;
	interrupt-map-mask = <0xffffffff>;
	interrupt-map = <0 &intc 0 125 0
			1 &intc 0 221 0
			2 &msm_gpio 67 0>;
	interrupt-names = "hc_irq", "pwr_irq", "status_irq";
	cd-gpios = <&msm_gpio 67 0x0>;
	//cd-inverted = <0>;
	qcom,bus-speed-mode = "SDR12", "SDR25", "SDR50", "DDR50";// remove , "SDR104"; 

	status = "ok";
};
/* wangyadong add dts for mmc0 & mmc1 end */

/* anxinlong@yulong.com add dts for long press power key action 20150729 start */

&spmi_bus {
       qcom,pm8950@0 {

qcom,power-on@800 {
			
			    qcom,pon_1 {
                        qcom,support-reset = <1>;
                        qcom,s1-timer = <6720>;
			            qcom,s2-timer = <2000>;
			            qcom,s2-type = <4>;
			 };
		 };
      };
 };
/* anxinlong@yulong.com add dts for long press power key action 20150729 end */

/* fuzicheng@yulong.com add dts for charger 20150730 start */
&spmi_bus {

	 qcom,pmi8950@2 {
              /delete-node/ qcom,leds@a100;
                        };
};

/* fuzicheng@yulong.com add dts for charger 20150730 end */

/* start william add dtsi for related lcd*/
/* qcom original file: msm8952-mtp.dtsi */
#include "yulong-dsi-panel-otm1901a-tianma-ips-fhd-550-video.dtsi"
#include "yulong-dsi-panel-otm1901a-tianma-id31-fhd-550-video.dtsi"
#include "yulong-dsi-panel-otm1901a-lide-lg-fhd-550-video.dtsi"
#include "yulong-dsi-panel-nt35596-yashi-auo-fhd-550-video.dtsi"
#include "yulong-dsi-panel-nt35596-boyi-auo-fhd-550-video.dtsi"
#include "yulong-dsi-panel-nt35695-sharp-fhd-550-video.dtsi"

&dsi_otm1901a_tianma_ips_fhd_vid {
	qcom,cont-splash-enabled;
	qcom,panel-supply-entries = <&dsi_panel_pwr_supply>;
};
&dsi_otm1901a_tianma_id31_fhd_vid {
	qcom,cont-splash-enabled;
	qcom,panel-supply-entries = <&dsi_panel_pwr_supply>;
};
&dsi_otm1901a_lide_lg_fhd_vid {
	qcom,cont-splash-enabled;
	qcom,panel-supply-entries = <&dsi_panel_pwr_supply>;
};
&dsi_nt35596_yashi_auo_fhd_vid {
	qcom,cont-splash-enabled;
	qcom,panel-supply-entries = <&dsi_panel_pwr_supply>;
};
&dsi_nt35596_boyi_auo_fhd_vid {
        qcom,cont-splash-enabled;
        qcom,panel-supply-entries = <&dsi_panel_pwr_supply>;
};
&dsi_nt35695_sharp_fhd_vid {
        qcom,cont-splash-enabled;
        qcom,panel-supply-entries = <&dsi_panel_pwr_supply>;
};
&pmx_mdss {
	qcom,num-grp-pins = <2>;
	qcom,pins = <&gp 33>, <&gp 89>;
};

&mdss_dsi0 {
	pinctrl-names = "mdss_default", "mdss_sleep";
	pinctrl-0 = <&mdss_dsi_active &mdss_te_active>;
	pinctrl-1 = <&mdss_dsi_suspend &mdss_te_suspend>;
	qcom,dsi-pref-prim-pan = <&dsi_nt35695_sharp_fhd_vid>;
	qcom,regulator-ldo-mode;
	qcom,platform-vddi-enable-gpio = <&msm_gpio 33 0>;
	qcom,platform-reset-gpio = <&msm_gpio 89 0>;
	/delete-property/ qcom,platform-enable-gpio;
	/delete-property/ qcom,platform-bklight-en-gpio;
};
/* qcom original file: msm8952-mtp.dtsi */

/* qcom original file: msm8952-mdss.dtsi */
&soc {
	mdss_mdp: qcom,mdss_mdp@1a00000 {
		mdss_fb0: qcom,mdss_fb_primary {
			/delete-property/ qcom,mdss-fb-splash-logo-enabled;
		};
	};

	mdss_dsi: qcom,mdss_dsi@0 {
		mdss_dsi0: qcom,mdss_dsi_ctrl0@1a98000 {
			/delete-property/ vdd-supply; /*vdd-supply = <&pm8950_l17>;*/
		};
	};
};
/* qcom original file: msm8952-mdss.dtsi */

/* qcom original file: msm8952-mdss-panels.dtsi */
&soc {
	dsi_panel_pwr_supply: dsi_panel_pwr_supply {
		/delete-node/ qcom,panel-supply-entry@0;
	};
};
/* qcom original file: msm8952-mdss-panels.dtsi */

/* qcom original file: msm-pmi8950.dtsi */
&spmi_bus {

	qcom,pmi8950@3 {
		qcom,leds@d800 {
			qcom,fs-curr-ua = <20000>;
		};
	};
};
/* qcom original file: msm-pmi8950.dtsi */
/* end william add dtsi for related lcd*/

&soc {
	gpio_keys {
	/delete-node/ camera_focus;
	/delete-node/ camera_snapshot;
	};
};

&slim_msm {
	tomtom_codec {
	/delete-property/ qcom,cdc-reset-gpio;
	};
};
	
